# STM32H5E5 register map
File version: 1.0
CPU: CM33 r0p0, little endian, MPU, FPU, 4 interrupt priority bits
Registers are 32-bit, read-write, reset 0x0 unless marked. A register's access mark holds for its fields unless they carry their own. Offsets are from the block's base; [hi:lo] are bit positions; {n}, {i} and the like mark numbered series.

## PSSI — PSSI register block
Base 0x4202C400
Same registers: PSSI_S 0x5202C400
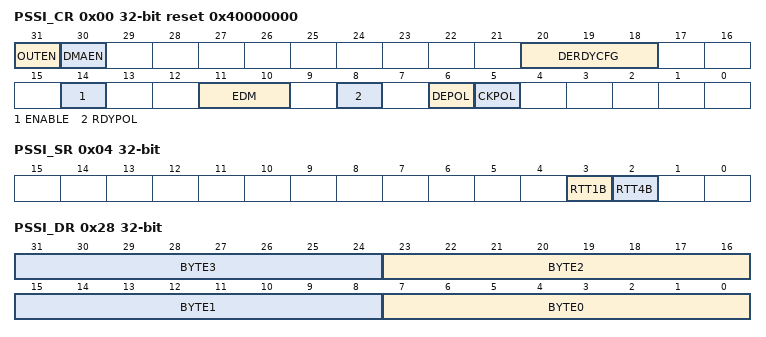
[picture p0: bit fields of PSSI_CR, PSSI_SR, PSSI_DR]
0x00 PSSI_CR reset 0x40000000 — PSSI control register
  [31] OUTEN — Data direction selection bit
    0=Receive mode: data is input synchronously with PSSI_PDCK; 1=Transmit mode: data is output synchronously with PSSI_PDCK
  [30] DMAEN — DMA enable bit
    0=DMA transfers are disabled; 1=DMA transfers are enabled (default configuration)
  [20:18] DERDYCFG — Data enable and ready configuration
    0=PSSI_DE and PSSI_RDY both disabled; 1=Only PSSI_RDY enabled; 2=Only PSSI_DE enabled; 3=Both PSSI_RDY and PSSI_DE alternate functions enabled; 4=Both PSSI_RDY and PSSI_DE features enabled - bidirectional on PSSI_RDY pin (see Bidirectional PSSI_DE/PSSI_RDY signal on page1659); 5=Only PSSI_RDY function enabled, but mapped to PSSI_DE pin; 6=Only PSSI_DE function enabled, but mapped to PSSI_RDY pin; 7=Both PSSI_RDY and PSSI_DE features enabled - bidirectional on PSSI_DE pin (see Bidirectional PSSI_DE/PSSI_RDY signal on page1659)
  [14] ENABLE — PSSI enable
    0=PSSI disabled; 1=PSSI enabled
  [11:10] EDM — Extended data mode
    0=Interface captures 8-bit data on every parallel data clock; 3=The interface captures 16-bit data on every parallel data clock
  [8] RDYPOL — Ready (PSSI_RDY) polarity
    0=PSSI_RDY active low (0 indicates that the receiver is ready to receive); 1=PSSI_RDY active high (1 indicates that the receiver is ready to receive)
  [6] DEPOL — Data enable (PSSI_DE) polarity
    0=PSSI_DE active low (0 indicates that data is valid); 1=PSSI_DE active high (1 indicates that data is valid)
  [5] CKPOL — Parallel data clock polarity
    0=Falling edge active for inputs or rising edge active for outputs; 1=Rising edge active for inputs or falling edge active for outputs
0x04 PSSI_SR ro — PSSI status register
  [3] RTT1B — FIFO is ready to transfer one byte
    1=FIFO is ready for a one byte (32-bit) transfer; 0=FIFO is not ready for a 1-byte transfer
  [2] RTT4B — FIFO is ready to transfer four bytes
    1=FIFO is ready for a four-byte (32-bit) transfer; 0=FIFO is not ready for a four-byte transfer
0x08 PSSI_RIS ro — PSSI raw interrupt status register
  [1] OVR_RIS — Data buffer overrun/underrun raw interrupt status
    0=No overrun/underrun occurred; 1=An overrun/underrun occurred: overrun in receive mode, underrun in transmit mode
0x0C PSSI_IER — PSSI interrupt enable register
  [1] OVR_IE — Data buffer overrun/underrun interrupt enable
    0=No interrupt generation; 1=An interrupt is generated if either an overrun or an underrun error occurred
0x10 PSSI_MIS ro — PSSI masked interrupt status register
  [1] OVR_MIS — Data buffer overrun/underrun masked interrupt status
    0=No interrupt is generated when an overrun/underrun error occurs; 1=An interrupt is generated if there is either an overrun or an underrun error and the OVR_IE bit is set in PSSI_IER
0x14 PSSI_ICR wo — PSSI interrupt clear register
  [1] OVR_ISC — Data buffer overrun/underrun interrupt status clear
0x28 PSSI_DR — PSSI data register
  [8n+7:8n] BYTE{n} (n=0..3) — Data byte {n}

## RNG — RNG address block description
Base 0x420C0800
Same registers: RNG_S 0x520C0800
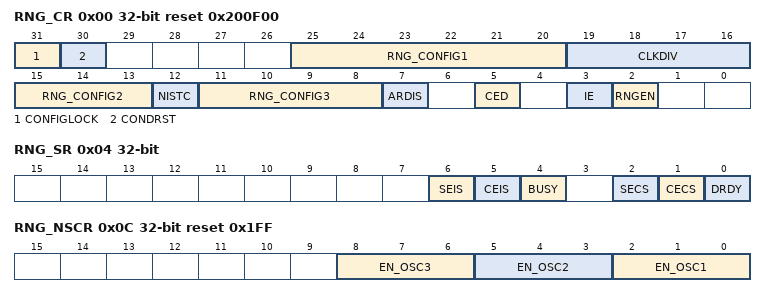
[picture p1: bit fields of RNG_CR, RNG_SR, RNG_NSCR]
0x00 RNG_CR reset 0x200F00 — RNG control register
  [31] CONFIGLOCK — RNG Config lock
    0=Writes to the RNG_NSCR, RNG_HTCR and the RNG_CR configuration bits [29:4] are allowed; 1=Writes to the RNG_NSCR, RNG_HTCR and the RNG_CR configuration bits [29:4] are ignored until the next RNG reset
  [30] CONDRST — Conditioning soft reset
  [25:20] RNG_CONFIG1 — RNG configuration 1
  [19:16] CLKDIV — Clock divider factor
    0=internal RNG clock after divider is similar to incoming RNG clock; 1=two RNG clock cycles per internal RNG clock; 2=2less thansup>2less than/sup> (= 4) RNG clock cycles per internal RNG clock; 15=2less thansup>15less than/sup> RNG clock cycles per internal clock (for example
  [15:13] RNG_CONFIG2 — RNG configuration 2
  [12] NISTC — NIST custom
    0=Hardware default values for NIST compliant RNG; 1=Custom values for NIST compliant RNG
  [11:8] RNG_CONFIG3 — RNG configuration 3
  [7] ARDIS — Auto reset disable
    0=Auto-reset is enabled; 1=Auto-reset is disabled
  [5] CED — Clock error detection
    0=Clock error detection is enabled; 1=Clock error detection is disabled
  [3] IE — Interrupt enable
    0=RNG interrupt is disabled; 1=RNG interrupt is enabled
  [2] RNGEN — True random number generator enable
    0=True random number generator disabled; 1=True random number generator enabled
0x04 RNG_SR — RNG status register
  [6] SEIS — Seed error interrupt status
    0=No faulty sequence detected; 1=At least one faulty sequence is detected
  [5] CEIS — Clock error interrupt status
    0=The RNG clock is correct (fless thansub>RNGCLKless than/sub>> fless thansub>HCLKless than/sub>/32); 1=The RNG clock before the internal divider is detected too slow (fless thansub>RNGCLKless than/sub>less than fless thansub>HCLKless than/sub>/32)
  [4] BUSY ro
    0=Idle; 1=Busy
  [2] SECS ro — Seed error current status
    0=No faulty sequence has currently been detected; 1=At least one of the following faulty sequence has been detected:
  [1] CECS ro — Clock error current status
    0=The RNG clock is correct (fless thansub>RNGCLKless than/sub>> fless thansub>HCLKless than/sub>/32); 1=The RNG clock is too slow (fless thansub>RNGCLKless than/sub>less than fless thansub>HCLKless than/sub>/32)
  [0] DRDY ro — Data ready
    0=No valid random data ready; 1=Valid random data ready
0x08 RNG_DR ro — RNG data register
  [31:0] RNDATA — Random data
0x0C RNG_NSCR reset 0x1FF — RNG noise source control register
  [8:6] EN_OSC3 — Each bit drives one oscillator enable signal input of instance number 3, gated with the RNGEN bit in RNG_CR (set bit to enable the oscillator).
  [5:3] EN_OSC2 — Each bit drives one oscillator enable signal input of instance number 2, gated with the RNGEN bit in RNG_CR (set bit to enable the oscillator).
  [2:0] EN_OSC1 — Each bit drives one oscillator enable signal input of instance number 1, gated with the RNGEN bit in RNG_CR (set bit to enable the oscillator).
0x10 RNG_HTCR0 reset 0x72AC — RNG health test control register 0
  [31:0] HTCFG — health test configuration
{0x10+4i} RNG_HTCR{i} reset 0xFFFF (i=1..3) — RNG health test control register {i}
  [31:0] HTCFG — health test configuration
